AUTOSAR XML (schema 4-2-2)
standard types defined: boolean, float32, float64, uint16, uint32, uint64, uint8
package /DataTypes/Base
  12 x base type, all with category=FIXED_LENGTH:
    bool_base: base-type-size=8, base-type-encoding=BOOLEAN, native-declaration=boolean
    boolean_base: base-type-size=8, base-type-encoding=BOOLEAN, native-declaration=boolean
    float32_base: base-type-size=32, base-type-encoding=IEEE754, native-declaration=float
    float64_base: base-type-size=64, base-type-encoding=IEEE754, native-declaration=double
    int16_base: base-type-size=16, base-type-encoding=2C, native-declaration=int16_t
    int32_base: base-type-size=32, base-type-encoding=2C, native-declaration=int32_t
    int64_base: base-type-size=64, base-type-encoding=2C, native-declaration=int64_t
    int8_base: base-type-size=8, base-type-encoding=2C, native-declaration=int8_t
    uint16_base: base-type-size=16, base-type-encoding=NONE, native-declaration=uint16_t
    uint32_base: base-type-size=32, base-type-encoding=NONE, native-declaration=uint32_t
    uint64_base: base-type-size=64, base-type-encoding=NONE, native-declaration=uint64_t
    uint8_base: base-type-size=8, base-type-encoding=NONE, native-declaration=uint8_t
package /DataTypes/Implementation
  5 x impl type, all with category=VALUE:
    bool: base-type=bool_base
    int16: base-type=int16_base
    int32: base-type=int32_base
    int64: base-type=int64_base
    int8: base-type=int8_base
package /PortInterfaces
  client server interface IDiagnosticService
    operation ReadDtc
      arg dtc_id: type=uint16, direction=IN, server-argument-impl-policy=USE-ARGUMENT-TYPE
      arg status: type=uint8, direction=OUT, server-argument-impl-policy=USE-ARGUMENT-TYPE
    operation ClearDtc
      arg dtc_id: type=uint16, direction=IN, server-argument-impl-policy=USE-ARGUMENT-TYPE
      arg result: type=uint8, direction=OUT, server-argument-impl-policy=USE-ARGUMENT-TYPE
  sender receiver interface IExample
    data value: type=float32
package /ComponentTypes
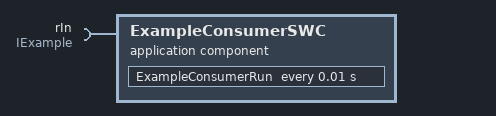
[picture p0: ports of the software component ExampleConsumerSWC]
  application sw component type ExampleConsumerSWC  # Example software component consuming data from ExampleSWC
    require port rIn: nonqueued-receiver-com-spec=data-element=value, required-interface=IExample  # Example input port requiring data
    behavior ExampleConsumerSWC_InternalBehavior: handle-termination-and-restart=NO-SUPPORT
      timing event TMT_ExampleConsumerRun: start-on-event=ExampleConsumerRun, period=0.01
      runnable ExampleConsumerRun: minimum-start-interval=0.01
  swc implementation ExampleConsumerSWC_Implementation: behavior=ExampleConsumerSWC_InternalBehavior
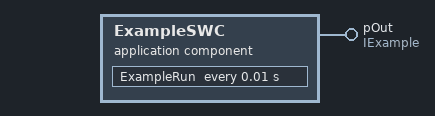
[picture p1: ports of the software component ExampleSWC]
  application sw component type ExampleSWC  # Example software component for testing and demonstration
    provide port pOut: nonqueued-sender-com-spec=data-element=value, provided-interface=IExample  # Example output port providing data
    behavior ExampleSWC_InternalBehavior: handle-termination-and-restart=NO-SUPPORT
      timing event TMT_ExampleRun: start-on-event=ExampleRun, period=0.01
      runnable ExampleRun: minimum-start-interval=0.01
  swc implementation ExampleSWC_Implementation: behavior=ExampleSWC_InternalBehavior
  composition sw component type Root  # Root composition | The top of the hierarchy: every component this project declares stands in it once, and the connector between them is drawn inside it. A connector that names no composition belongs to the root, which is why Example_to_Consumer carries no `composition:` key.
    component ExampleSWC: type=ExampleSWC  # The provider of IExample.
    component ExampleConsumerSWC: type=ExampleConsumerSWC  # The consumer of IExample.
    connect ExampleSWC.pOut -> ExampleConsumerSWC.rIn  # ExampleSWC provides IExample data to ExampleConsumerSWC
